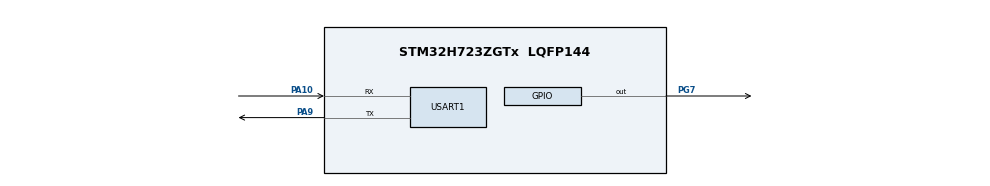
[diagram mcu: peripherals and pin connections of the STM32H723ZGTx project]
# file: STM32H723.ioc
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Mcu.Family=STM32H7
Mcu.Name=STM32H723ZGTx
Mcu.Package=LQFP144
NVIC.PriorityGroup=NVIC_PRIORITYGROUP_4
NVIC.TIM6_DAC_IRQn=true\:15\:0\:false\:false\:true\:false\:true\:true
NVIC.TimeBase=TIM6_DAC_IRQn
NVIC.TimeBaseIP=TIM6
PA10.GPIO_Speed=GPIO_SPEED_FREQ_MEDIUM
PA10.Mode=Asynchronous
PA10.Signal=USART1_RX
PA9.GPIO_Speed=GPIO_SPEED_FREQ_MEDIUM
PA9.Mode=Asynchronous
PA9.Signal=USART1_TX
PG7.Signal=GPIO_Output
PH0-OSC_IN.Mode=HSE-External-Oscillator
PH0-OSC_IN.Signal=RCC_OSC_IN
PH1-OSC_OUT.Mode=HSE-External-Oscillator
PH1-OSC_OUT.Signal=RCC_OSC_OUT
ProjectManager.HeapSize=0x2000
ProjectManager.StackSize=0x4000
ProjectManager.TargetToolchain=MDK-ARM V5.32
RCC.ADCFreq_Value=50390625
RCC.APB1Freq_Value=137500000
RCC.APB2Freq_Value=137500000
RCC.APB3Freq_Value=137500000
RCC.APB4Freq_Value=137500000
RCC.CortexFreq_Value=550000000
RCC.D1PPRE=RCC_APB3_DIV2
RCC.D2PPRE1=RCC_APB1_DIV2
RCC.D2PPRE2=RCC_APB2_DIV2
RCC.D3PPRE=RCC_APB4_DIV2
RCC.DIVM1=5
RCC.DIVN1=110
RCC.DIVP1=1
RCC.HCLKFreq_Value=275000000
RCC.HPRE=RCC_HCLK_DIV2
RCC.PLLSourceVirtual=RCC_PLLSOURCE_HSE
RCC.SYSCLKFreq_VALUE=550000000
RCC.SYSCLKSource=RCC_SYSCLKSOURCE_PLLCLK
RCC.USBFreq_Value=275000000
USART1.VirtualMode-Asynchronous=VM_ASYNC
VP_MEMORYMAP_VS_MEMORYMAP.Mode=CurAppReg
VP_SYS_VS_tim6.Mode=TIM6
board=custom

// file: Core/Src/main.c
/* USER CODE BEGIN Header */
/**
  ******************************************************************************
  * @file           : main.c
  * @brief          : Main program body
  ******************************************************************************
  * @attention
  *
  * Copyright (c) 2026 STMicroelectronics.
  * All rights reserved.
  *
  * This software is licensed under terms that can be found in the LICENSE file
  * in the root directory of this software component.
  * If no LICENSE file comes with this software, it is provided AS-IS.
  *
  ******************************************************************************
  */
/* USER CODE END Header */
#include "main.h"
#include "tx_api.h"
#include "netx_app.h"
UART_HandleTypeDef huart1;
ETH_HandleTypeDef heth;
static void MPU_Config(void);
void SystemClock_Config(void);
static void MX_GPIO_Init(void);
static void MX_USART1_UART_Init(void);
static void MX_ETH_Init(void);
void thread_error(void)
{
	unsigned int error_count = 0;
	while(1)
	{
		error_count++;
	}
}
#define 	RTOS_THREAD_STACK_SIZE			(2*1024)
#define		RTOS_BYTE_POOL_SIZE					(16*1024)

TX_BYTE_POOL	POOL_BYTES;
__ALIGN_BEGIN static UCHAR	memory_area[RTOS_BYTE_POOL_SIZE] __ALIGN_END;

TX_THREAD		led_thread;
void led_thread_entry(ULONG thread_input);

ETH_TxPacketConfig TxConfig;
ETH_DMADescTypeDef DMARxDscrTab[ETH_RX_DESC_CNT] __attribute__((section(".RxDescripSection"))); /* Ethernet Rx DMA Descriptors */
ETH_DMADescTypeDef DMATxDscrTab[ETH_TX_DESC_CNT] __attribute__((section(".TxDescripSection")));   /* Ethernet Tx DMA Descriptors */

int main(void)
{
	MPU_Config();
	SCB_EnableICache();
	SCB_EnableDCache();
  HAL_Init();
  SystemClock_Config();
  MX_GPIO_Init();
  MX_USART1_UART_Init();
	MX_ETH_Init();
	tx_kernel_enter();
  while (1);
}

void tx_application_define(void *first_unused_memory)
{
    CHAR    *pointer = TX_NULL;
		UINT		result = TX_SUCCESS;
    /* Create a byte memory pool from which to allocate the thread stacks.  */
    result = tx_byte_pool_create(&POOL_BYTES, "Tot MEM Pool", memory_area, RTOS_BYTE_POOL_SIZE);
		if(result)
			thread_error();

    /* Allocate the stack for LED Thread.  */
    result = tx_byte_allocate(&POOL_BYTES, (VOID **) &pointer, RTOS_THREAD_STACK_SIZE, TX_NO_WAIT);
		if(result)
			thread_error();

    /* Create the main thread.  */
    result = tx_thread_create(&led_thread, "LED Thread", led_thread_entry, 0,
                    pointer, RTOS_THREAD_STACK_SIZE,
                    10, 10, TX_NO_TIME_SLICE, TX_AUTO_START);

		if(result)
			thread_error();

		/* Init NetXDUO */
		result = MX_NetXDuo_Init();
		if(result)
			thread_error();

}

void led_thread_entry(ULONG thread_input)
{
	uint8_t flag=0;
	while(1)
	{
		if(flag)
			HAL_GPIO_WritePin(GPIOG, GPIO_PIN_7, GPIO_PIN_RESET);
		else
			HAL_GPIO_WritePin(GPIOG, GPIO_PIN_7, GPIO_PIN_SET);
		flag = ~flag;
		tx_thread_sleep(1000);
	}
}

void _tx_thread_stack_error_handler(TX_THREAD *thread_ptr)
{
	thread_error();
}
void SystemClock_Config(void)
{
  RCC_OscInitTypeDef RCC_OscInitStruct = {0};
  RCC_ClkInitTypeDef RCC_ClkInitStruct = {0};

  /** Supply configuration update enable
  */
  HAL_PWREx_ConfigSupply(PWR_LDO_SUPPLY);

  /** Configure the main internal regulator output voltage
  */
  __HAL_PWR_VOLTAGESCALING_CONFIG(PWR_REGULATOR_VOLTAGE_SCALE0);

  while(!__HAL_PWR_GET_FLAG(PWR_FLAG_VOSRDY)) {}

  /** Initializes the RCC Oscillators according to the specified parameters
  * in the RCC_OscInitTypeDef structure.
  */
  RCC_OscInitStruct.OscillatorType = RCC_OSCILLATORTYPE_HSE;
  RCC_OscInitStruct.HSEState = RCC_HSE_ON;
  RCC_OscInitStruct.PLL.PLLState = RCC_PLL_ON;
  RCC_OscInitStruct.PLL.PLLSource = RCC_PLLSOURCE_HSE;
  RCC_OscInitStruct.PLL.PLLM = 5;
  RCC_OscInitStruct.PLL.PLLN = 110;
  RCC_OscInitStruct.PLL.PLLP = 1;
  RCC_OscInitStruct.PLL.PLLQ = 2;
  RCC_OscInitStruct.PLL.PLLR = 2;
  RCC_OscInitStruct.PLL.PLLRGE = RCC_PLL1VCIRANGE_2;
  RCC_OscInitStruct.PLL.PLLVCOSEL = RCC_PLL1VCOWIDE;
  RCC_OscInitStruct.PLL.PLLFRACN = 0;
  if (HAL_RCC_OscConfig(&RCC_OscInitStruct) != HAL_OK)
  {
    Error_Handler();
  }

  /** Initializes the CPU, AHB and APB buses clocks
  */
  RCC_ClkInitStruct.ClockType = RCC_CLOCKTYPE_HCLK|RCC_CLOCKTYPE_SYSCLK
                              |RCC_CLOCKTYPE_PCLK1|RCC_CLOCKTYPE_PCLK2
                              |RCC_CLOCKTYPE_D3PCLK1|RCC_CLOCKTYPE_D1PCLK1;
  RCC_ClkInitStruct.SYSCLKSource = RCC_SYSCLKSOURCE_PLLCLK;
  RCC_ClkInitStruct.SYSCLKDivider = RCC_SYSCLK_DIV1;
  RCC_ClkInitStruct.AHBCLKDivider = RCC_HCLK_DIV2;
  RCC_ClkInitStruct.APB3CLKDivider = RCC_APB3_DIV2;
  RCC_ClkInitStruct.APB1CLKDivider = RCC_APB1_DIV2;
  RCC_ClkInitStruct.APB2CLKDivider = RCC_APB2_DIV2;
  RCC_ClkInitStruct.APB4CLKDivider = RCC_APB4_DIV2;

  if (HAL_RCC_ClockConfig(&RCC_ClkInitStruct, FLASH_LATENCY_3) != HAL_OK)
  {
    Error_Handler();
  }
}

static void MX_USART1_UART_Init(void)
{

  huart1.Instance = USART1;
  huart1.Init.BaudRate = 115200;
  huart1.Init.WordLength = UART_WORDLENGTH_8B;
  huart1.Init.StopBits = UART_STOPBITS_1;
  huart1.Init.Parity = UART_PARITY_NONE;
  huart1.Init.Mode = UART_MODE_TX_RX;
  huart1.Init.HwFlowCtl = UART_HWCONTROL_NONE;
  huart1.Init.OverSampling = UART_OVERSAMPLING_16;
  huart1.Init.OneBitSampling = UART_ONE_BIT_SAMPLE_DISABLE;
  huart1.Init.ClockPrescaler = UART_PRESCALER_DIV1;
  huart1.AdvancedInit.AdvFeatureInit = UART_ADVFEATURE_NO_INIT;
  if (HAL_UART_Init(&huart1) != HAL_OK)
  {
    Error_Handler();
  }
  if (HAL_UARTEx_SetTxFifoThreshold(&huart1, UART_TXFIFO_THRESHOLD_1_8) != HAL_OK)
  {
    Error_Handler();
  }
  if (HAL_UARTEx_SetRxFifoThreshold(&huart1, UART_RXFIFO_THRESHOLD_1_8) != HAL_OK)
  {
    Error_Handler();
  }
  if (HAL_UARTEx_DisableFifoMode(&huart1) != HAL_OK)
  {
    Error_Handler();
  }

}

static void MX_GPIO_Init(void)
{
  GPIO_InitTypeDef GPIO_InitStruct = {0};

  /* GPIO Ports Clock Enable */
  __HAL_RCC_GPIOH_CLK_ENABLE();
  __HAL_RCC_GPIOG_CLK_ENABLE();
  __HAL_RCC_GPIOA_CLK_ENABLE();

  /*Configure GPIO pin Output Level */
  HAL_GPIO_WritePin(GPIOG, GPIO_PIN_7, GPIO_PIN_RESET);

  /*Configure GPIO pin : PG7 */
  GPIO_InitStruct.Pin = GPIO_PIN_7;
  GPIO_InitStruct.Mode = GPIO_MODE_OUTPUT_PP;
  GPIO_InitStruct.Pull = GPIO_NOPULL;
  GPIO_InitStruct.Speed = GPIO_SPEED_FREQ_LOW;
  HAL_GPIO_Init(GPIOG, &GPIO_InitStruct);

}

/* USER CODE BEGIN 4 */
static void MX_ETH_Init(void)
{

  /* USER CODE BEGIN ETH_Init 0 */

  /* USER CODE END ETH_Init 0 */

   static uint8_t MACAddr[6];

  /* USER CODE BEGIN ETH_Init 1 */

  /* USER CODE END ETH_Init 1 */
  heth.Instance = ETH;
  MACAddr[0] = 0x00;
  MACAddr[1] = 0x80;
  MACAddr[2] = 0xE1;
  MACAddr[3] = 0x00;
  MACAddr[4] = 0x30;
  MACAddr[5] = 0x20;
  heth.Init.MACAddr = &MACAddr[0];
  heth.Init.MediaInterface = HAL_ETH_RMII_MODE;
  heth.Init.TxDesc = DMATxDscrTab;
  heth.Init.RxDesc = DMARxDscrTab;
  heth.Init.RxBuffLen = 1536;

  /* USER CODE BEGIN MACADDRESS */

  /* USER CODE END MACADDRESS */

  if (HAL_ETH_Init(&heth) != HAL_OK)
  {
    Error_Handler();
  }

  memset(&TxConfig, 0 , sizeof(ETH_TxPacketConfig));
  TxConfig.Attributes = ETH_TX_PACKETS_FEATURES_CSUM | ETH_TX_PACKETS_FEATURES_CRCPAD;
  TxConfig.ChecksumCtrl = ETH_CHECKSUM_IPHDR_PAYLOAD_INSERT_PHDR_CALC;
  TxConfig.CRCPadCtrl = ETH_CRC_PAD_INSERT;
  /* USER CODE BEGIN ETH_Init 2 */

  /* USER CODE END ETH_Init 2 */
}
/* USER CODE END 4 */

 /* MPU Configuration */

static void MPU_Config(void)
{
  MPU_Region_InitTypeDef MPU_InitStruct = {0};

  /* Disables the MPU */
  HAL_MPU_Disable();

//  /** Initializes and configures the Region and the memory to be protected
//  */
//  MPU_InitStruct.Enable = MPU_REGION_ENABLE;
//  MPU_InitStruct.Number = MPU_REGION_NUMBER0;
//  MPU_InitStruct.BaseAddress = 0x0;
//  MPU_InitStruct.Size = MPU_REGION_SIZE_4GB;
//  MPU_InitStruct.SubRegionDisable = 0x87;
//  MPU_InitStruct.TypeExtField = MPU_TEX_LEVEL0;
//  MPU_InitStruct.AccessPermission = MPU_REGION_NO_ACCESS;
//  MPU_InitStruct.DisableExec = MPU_INSTRUCTION_ACCESS_DISABLE;
//  MPU_InitStruct.IsShareable = MPU_ACCESS_SHAREABLE;
//  MPU_InitStruct.IsCacheable = MPU_ACCESS_NOT_CACHEABLE;
//  MPU_InitStruct.IsBufferable = MPU_ACCESS_NOT_BUFFERABLE;

//  HAL_MPU_ConfigRegion(&MPU_InitStruct);

  /** Initializes and configures the Region and the memory to be protected
  */
	MPU_InitStruct.Enable = MPU_REGION_ENABLE;
  MPU_InitStruct.Number = MPU_REGION_NUMBER0;
  MPU_InitStruct.BaseAddress = 0x30000000;
  MPU_InitStruct.Size = MPU_REGION_SIZE_32KB;
  MPU_InitStruct.SubRegionDisable = 0x0;
  MPU_InitStruct.AccessPermission = MPU_REGION_FULL_ACCESS;
  MPU_InitStruct.DisableExec = MPU_INSTRUCTION_ACCESS_ENABLE;
  MPU_InitStruct.IsShareable = MPU_ACCESS_NOT_SHAREABLE;
  MPU_InitStruct.IsCacheable = MPU_ACCESS_CACHEABLE;
	MPU_InitStruct.IsBufferable = MPU_ACCESS_NOT_BUFFERABLE;
  HAL_MPU_ConfigRegion(&MPU_InitStruct);

  MPU_InitStruct.Number = MPU_REGION_NUMBER1;
  MPU_InitStruct.Size = MPU_REGION_SIZE_1KB;
  MPU_InitStruct.IsCacheable = MPU_ACCESS_NOT_CACHEABLE;
  MPU_InitStruct.IsShareable = MPU_ACCESS_SHAREABLE;

  HAL_MPU_ConfigRegion(&MPU_InitStruct);
  /** Initializes and configures the Region and the memory to be protected
  */

  MPU_InitStruct.Number = MPU_REGION_NUMBER2;
  MPU_InitStruct.BaseAddress = 0x24000000;
  MPU_InitStruct.Size = MPU_REGION_SIZE_256KB;
  MPU_InitStruct.IsCacheable = MPU_ACCESS_CACHEABLE;
  MPU_InitStruct.IsShareable = MPU_ACCESS_NOT_SHAREABLE;

  HAL_MPU_ConfigRegion(&MPU_InitStruct);

  MPU_InitStruct.Number = MPU_REGION_NUMBER3;
  MPU_InitStruct.BaseAddress = 0x24040000;
  MPU_InitStruct.Size = MPU_REGION_SIZE_64KB;
	HAL_MPU_ConfigRegion(&MPU_InitStruct);
  /* Enables the MPU */
  HAL_MPU_Enable(MPU_PRIVILEGED_DEFAULT);

}

void HAL_TIM_PeriodElapsedCallback(TIM_HandleTypeDef *htim)
{
  if (htim->Instance == TIM6)
  {
    HAL_IncTick();
  }
}

void Error_Handler(void)
{
  __disable_irq();
  while (1)
  {
  }
}
